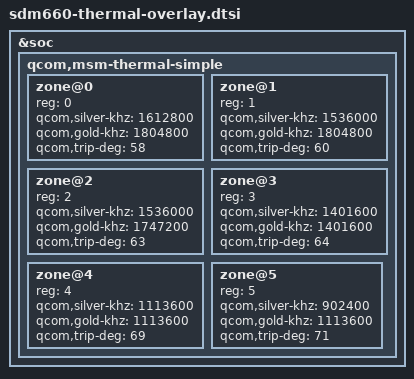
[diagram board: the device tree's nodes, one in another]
/* SPDX-License-Identifier: GPL-2.0 */

&soc {
	qcom,msm-thermal-simple {
	zone@0 {
			reg = <0>;
			qcom,silver-khz = <1612800>;
			qcom,gold-khz = <1804800>;
			qcom,trip-deg = <58>;
		};
	};
};

&soc {
	qcom,msm-thermal-simple {
	zone@1 {
			reg = <1>;
			qcom,silver-khz = <1536000>;
			qcom,gold-khz = <1804800>;
			qcom,trip-deg = <60>;
		};
	};
};

&soc {
	qcom,msm-thermal-simple {
		zone@2 {
			reg = <2>;
			qcom,silver-khz = <1536000>;
			qcom,gold-khz = <1747200>;
			qcom,trip-deg = <63>;
		};
	};
};

&soc {
	qcom,msm-thermal-simple {
		zone@3 {
			reg = <3>;
			qcom,silver-khz = <1401600>;
			qcom,gold-khz = <1401600>;
			qcom,trip-deg = <64>;
		};
	};
};

&soc {
	qcom,msm-thermal-simple {
		zone@4 {
			reg = <4>;
			qcom,silver-khz = <1113600>;
			qcom,gold-khz = <1113600>;
			qcom,trip-deg = <69>;
		};
	};
};

&soc {
	qcom,msm-thermal-simple {
		zone@5 {
			reg = <5>;
			qcom,silver-khz = <902400>;
			qcom,gold-khz = <1113600>;
			qcom,trip-deg = <71>;
		};
	};
};
